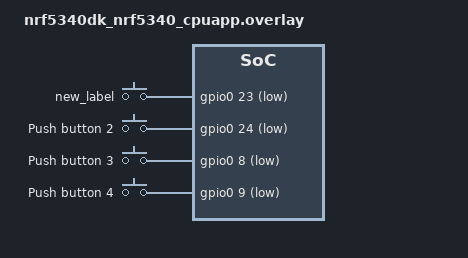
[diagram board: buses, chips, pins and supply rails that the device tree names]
/{
    buttons {
		compatible = "bms-pins";
		button0_2: button_0_2 {
			gpios = <&gpio0 23 (GPIO_PULL_UP | GPIO_ACTIVE_LOW)>;
			label = "new_label";
		};
		button1_2: button_1_2 {
			gpios = <&gpio0 24 (GPIO_PULL_UP | GPIO_ACTIVE_LOW)>;
			label = "Push button 2";
		};
		button2_2: button_2_2 {
			gpios = <&gpio0 8 (GPIO_PULL_UP | GPIO_ACTIVE_LOW)>;
			label = "Push button 3";
		};
		button3_2: button_3_2 {
			gpios = <&gpio0 9 (GPIO_PULL_UP | GPIO_ACTIVE_LOW)>;
			label = "Push button 4";
		};
	};
    aliases {
		sw02 = &button0_2;
		sw12 = &button1_2;
		sw22 = &button2_2;
		sw32 = &button3_2;
	};
};

